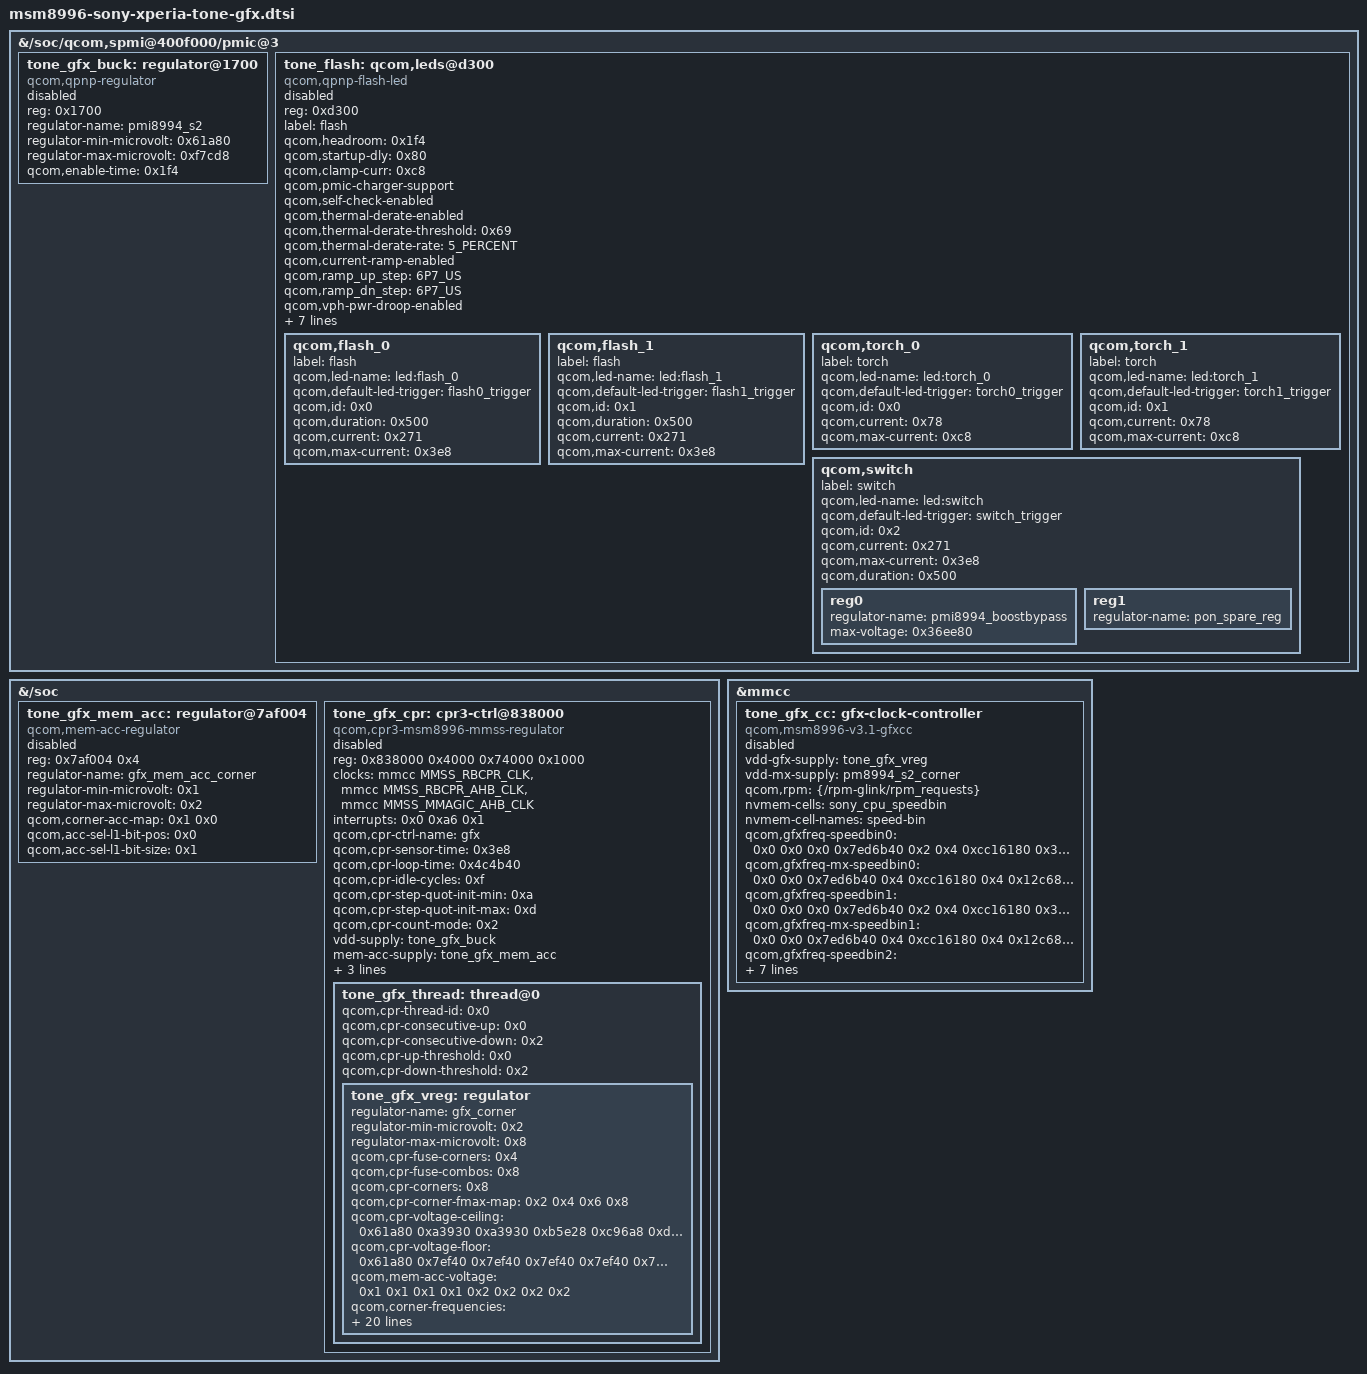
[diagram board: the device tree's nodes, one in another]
/* Copyright (c) 2014-2017, The Linux Foundation. All rights reserved.
 *
 * This program is free software; you can redistribute it and/or modify
 * it under the terms of the GNU General Public License version 2 and
 * only version 2 as published by the Free Software Foundation.
 */
/* Hardware data from the final Sony dora DT at
 * 0c295b15b6d0fb59a64e13b9e0ef2070818ef2a1, not intermediate includes.
 * Source data is retained while unsupported power chains remain disabled.
 */

#include <dt-bindings/clock/qcom,mmcc-msm8996.h>
#include "msm8996-sony-xperia-tone-corners.dtsi"

/* Preserve the original PMIC buck contract. The old qpnp-regulator frontend
 * has not been ported. Do not substitute an unverified multi-rail native
 * container: registering extra rails can alter their boot state at late init.
 */
&{/soc/qcom,spmi@400f000/pmic@3} {
	tone_gfx_buck: regulator@1700 {
		compatible = "qcom,qpnp-regulator";
		reg = <0x1700>;
		regulator-name = "pmi8994_s2";
		regulator-min-microvolt = <0x61a80>;
		regulator-max-microvolt = <0xf7cd8>;
		qcom,enable-time = <0x1f4>;
		status = "disabled";
	};

/* Legacy Sony flash safety policy; the matching VADC/charger/boost driver
	 * is not ported. A FLASH_V2 compatible does not describe this hardware. */
	tone_flash: qcom,leds@d300 {
		compatible = "qcom,qpnp-flash-led";
		reg = <0xd300>;
		label = "flash";
		qcom,headroom = <0x1f4>;
		qcom,startup-dly = <0x80>;
		qcom,clamp-curr = <0xc8>;
		qcom,pmic-charger-support;
		qcom,self-check-enabled;
		qcom,thermal-derate-enabled;
		qcom,thermal-derate-threshold = <0x69>;
		qcom,thermal-derate-rate = "5_PERCENT";
		qcom,current-ramp-enabled;
		qcom,ramp_up_step = "6P7_US";
		qcom,ramp_dn_step = "6P7_US";
		qcom,vph-pwr-droop-enabled;
		qcom,vph-pwr-droop-threshold = <0xbb8>;
		qcom,vph-pwr-droop-debounce-time = <0xa>;
		qcom,headroom-sense-ch0-enabled;
		qcom,headroom-sense-ch1-enabled;
		qcom,power-detect-enabled;
		qcom,pmic-revid = <&pmi8994_revid>;
		qcom,follow-otst2-rb-disabled;
		status = "disabled";

		qcom,flash_0 {
			label = "flash";
			qcom,led-name = "led:flash_0";
			qcom,default-led-trigger = "flash0_trigger";
			qcom,id = <0x0>;
			qcom,duration = <0x500>;
			qcom,current = <0x271>;
			qcom,max-current = <0x3e8>;
		};

		qcom,flash_1 {
			label = "flash";
			qcom,led-name = "led:flash_1";
			qcom,default-led-trigger = "flash1_trigger";
			qcom,id = <0x1>;
			qcom,duration = <0x500>;
			qcom,current = <0x271>;
			qcom,max-current = <0x3e8>;
		};

		qcom,torch_0 {
			label = "torch";
			qcom,led-name = "led:torch_0";
			qcom,default-led-trigger = "torch0_trigger";
			qcom,id = <0x0>;
			qcom,current = <0x78>;
			qcom,max-current = <0xc8>;
		};

		qcom,torch_1 {
			label = "torch";
			qcom,led-name = "led:torch_1";
			qcom,default-led-trigger = "torch1_trigger";
			qcom,id = <0x1>;
			qcom,current = <0x78>;
			qcom,max-current = <0xc8>;
		};

		qcom,switch {
			label = "switch";
			qcom,led-name = "led:switch";
			qcom,default-led-trigger = "switch_trigger";
			qcom,id = <0x2>;
			qcom,current = <0x271>;
			qcom,max-current = <0x3e8>;
			qcom,duration = <0x500>;

			reg0 {
				regulator-name = "pmi8994_boostbypass";
				max-voltage = <0x36ee80>;
			};

			reg1 {
				regulator-name = "pon_spare_reg";
			};
		};
	};
};

&{/soc} {
	tone_gfx_mem_acc: regulator@7af004 {
		compatible = "qcom,mem-acc-regulator";
		reg = <0x7af004 0x4>;
		reg-names = "acc-sel-l1";
		regulator-name = "gfx_mem_acc_corner";
		regulator-min-microvolt = <0x1>;
		regulator-max-microvolt = <0x2>;
		qcom,corner-acc-map = <0x1 0x0>;
		qcom,acc-sel-l1-bit-pos = <0x0>;
		qcom,acc-sel-l1-bit-size = <0x1>;
		status = "disabled";
	};

	tone_gfx_cpr: cpr3-ctrl@838000 {
		compatible = "qcom,cpr3-msm8996-mmss-regulator";
		reg = <0x838000 0x4000 0x74000 0x1000>;
		reg-names = "cpr_ctrl", "fuse_base";
		clocks = <&mmcc MMSS_RBCPR_CLK>, <&mmcc MMSS_RBCPR_AHB_CLK>,
			 <&mmcc MMSS_MMAGIC_AHB_CLK>;
		clock-names = "core_clk", "iface_clk", "bus_clk";
		interrupts = <0x0 0xa6 0x1>;
		interrupt-names = "cpr";
		qcom,cpr-ctrl-name = "gfx";
		qcom,cpr-sensor-time = <0x3e8>;
		qcom,cpr-loop-time = <0x4c4b40>;
		qcom,cpr-idle-cycles = <0xf>;
		qcom,cpr-step-quot-init-min = <0xa>;
		qcom,cpr-step-quot-init-max = <0xd>;
		qcom,cpr-count-mode = <0x2>;
		vdd-supply = <&tone_gfx_buck>;
		mem-acc-supply = <&tone_gfx_mem_acc>;
		qcom,voltage-step = <0x1388>;
		qcom,cpr-enable;
		qcom,cpr-aging-ref-voltage = <0xdcf28>;
		status = "disabled";

		tone_gfx_thread: thread@0 {
			qcom,cpr-thread-id = <0x0>;
			qcom,cpr-consecutive-up = <0x0>;
			qcom,cpr-consecutive-down = <0x2>;
			qcom,cpr-up-threshold = <0x0>;
			qcom,cpr-down-threshold = <0x2>;

			tone_gfx_vreg: regulator {
				regulator-name = "gfx_corner";
				regulator-min-microvolt = <0x2>;
				regulator-max-microvolt = <0x8>;
				qcom,cpr-fuse-corners = <0x4>;
				qcom,cpr-fuse-combos = <0x8>;
				qcom,cpr-corners = <0x8>;
				qcom,cpr-corner-fmax-map = <0x2 0x4 0x6 0x8>;
				qcom,cpr-voltage-ceiling = <0x61a80 0xa3930 0xa3930 0xb5e28 0xc96a8 0xdcf28 0xea600 0xf7cd8>;
				qcom,cpr-voltage-floor = <0x61a80 0x7ef40 0x7ef40 0x7ef40 0x7ef40 0x7ef40 0x7ef40 0x7ef40>;
				qcom,mem-acc-voltage = <0x1 0x1 0x1 0x1 0x2 0x2 0x2 0x2>;
				qcom,corner-frequencies = <0x0 0x7ed6b40 0xcc16180 0x12c684c0 0x17f2fb40 0x1e65fb80 0x2160ec00 0x25317c00>;
				qcom,cpr-target-quotients = <0x0 0x0 0x0 0x0 0x0 0x0 0x0 0x0
			0x0 0x0 0x0 0x0 0x0 0x0 0x0 0x0
			0x0 0x0 0x0 0x0 0x0 0x0 0xb9 0xb3
			0x123 0x12b 0x130 0x13f 0x0 0x0 0x0 0x0
			0x0 0x0 0x0 0x0 0x0 0x0 0x11f 0x111
			0x1a9 0x1aa 0x1bb 0x1c5 0x0 0x0 0x0 0x0
			0x0 0x0 0x0 0x0 0x0 0x0 0x19e 0x188
			0x248 0x240 0x260 0x264 0x0 0x0 0x0 0x0
			0x0 0x0 0x0 0x0 0x0 0x0 0x1cb 0x1af
			0x2ac 0x284 0x2b4 0x2a7 0x0 0x0 0x0 0x0
			0x0 0x0 0x0 0x0 0x0 0x0 0x241 0x21f
			0x31e 0x300 0x337 0x32a 0x0 0x0 0x0 0x0
			0x0 0x0 0x0 0x0 0x0 0x0 0x29d 0x275
			0x376 0x360 0x39c 0x38f 0x0 0x0 0x0 0x0
			0x0 0x0 0x0 0x0 0x0 0x0 0x303 0x2d5
			0x3d8 0x3ca 0x40c 0x400 0x0 0x0 0x0 0x0>;
				qcom,cpr-ro-scaling-factor = <0x0 0x0 0x0 0x0 0x0 0x0 0x7f3 0x77d
			0x7a7 0x853 0x8c6 0x8cd 0x0 0x0 0x0 0x0
			0x0 0x0 0x0 0x0 0x0 0x0 0x7f3 0x77d
			0x7a7 0x853 0x8c6 0x8cd 0x0 0x0 0x0 0x0
			0x0 0x0 0x0 0x0 0x0 0x0 0x7f3 0x77d
			0x7a7 0x853 0x8c6 0x8cd 0x0 0x0 0x0 0x0
			0x0 0x0 0x0 0x0 0x0 0x0 0x7f3 0x77d
			0x7a7 0x853 0x8c6 0x8cd 0x0 0x0 0x0 0x0
			0x0 0x0 0x0 0x0 0x0 0x0 0x7f3 0x77d
			0x7a7 0x853 0x8c6 0x8cd 0x0 0x0 0x0 0x0
			0x0 0x0 0x0 0x0 0x0 0x0 0x7f3 0x77d
			0x7a7 0x853 0x8c6 0x8cd 0x0 0x0 0x0 0x0
			0x0 0x0 0x0 0x0 0x0 0x0 0x7f3 0x77d
			0x7a7 0x853 0x8c6 0x8cd 0x0 0x0 0x0 0x0
			0x0 0x0 0x0 0x0 0x0 0x0 0x7f3 0x77d
			0x7a7 0x853 0x8c6 0x8cd 0x0 0x0 0x0 0x0>;
				qcom,cpr-open-loop-voltage-fuse-adjustment = <0x0 0x0 0x7530 0xffffd8f0 0xffff8ad0 0xffff8ad0 0x0 0xffffd8f0
			0xffff8ad0 0xffff8ad0 0x0 0xffffd8f0 0xfffeee90 0x0 0x0 0x0
			0xfffeee90 0x0 0x0 0x0 0xfffeee90 0x0 0x0 0x0
			0xfffeee90 0x0 0x0 0x0 0xfffeee90 0x0 0x0 0x0>;
				qcom,cpr-closed-loop-voltage-adjustment = <0x0 0xafc8 0xffffec78 0x4e20 0x4e20 0x7530 0x2710 0xffffec78
			0x0 0xafc8 0xffffec78 0x4e20 0x4e20 0x7530 0x2710 0xffffec78
			0x0 0x7530 0xea60 0x9c40 0x9c40 0xafc8 0x61a8 0x88b8
			0x0 0x0 0x7530 0x2710 0x2710 0xafc8 0x61a8 0x61a8
			0x0 0x0 0x7530 0x2710 0x2710 0xafc8 0x61a8 0x61a8
			0x0 0x0 0x7530 0x2710 0x2710 0xafc8 0x61a8 0x61a8
			0x0 0x0 0x7530 0x2710 0x2710 0xafc8 0x61a8 0x61a8
			0x0 0x0 0x7530 0x2710 0x2710 0xafc8 0x61a8 0x61a8>;
				qcom,cpr-floor-to-ceiling-max-range = <0x0 0x11170 0x11170 0x124f8 0x13880 0x15f90 0x17318 0x186a0>;
				qcom,cpr-fused-closed-loop-voltage-adjustment-map = <0x0 0x0 0x0 0x0 0x0 0x0 0x0 0x0
			0x0 0x0 0x0 0x0 0x0 0x0 0x0 0x0
			0x0 0x0 0x0 0x0 0x0 0x0 0x0 0x0
			0x0 0x0 0x0 0x0 0x0 0x0 0x0 0x0
			0x0 0x2 0x2 0x2 0x2 0x0 0x0 0x4
			0x0 0x2 0x2 0x2 0x2 0x0 0x0 0x4
			0x0 0x2 0x2 0x2 0x2 0x0 0x0 0x4
			0x0 0x2 0x2 0x2 0x2 0x0 0x0 0x4>;
				qcom,allow-voltage-interpolation;
				qcom,cpr-scaled-open-loop-voltage-as-ceiling;
				qcom,cpr-aging-max-voltage-adjustment = <0x3a98>;
				qcom,cpr-aging-ref-corner = <0x6>;
				qcom,cpr-aging-ro-scaling-factor = <0xb86>;
				qcom,allow-aging-voltage-adjustment = <0x0 0x0 0x0 0x1 0x1 0x1 0x1 0x1>;
			};
		};
	};

};

/* Sony CPU/MMSS clock drivers share fuse bits 29..31 at 0x74130; use
 * the existing CPU supplement cell instead of duplicating its NVMEM range. */
/* Child uses MMCC's single regmap owner; CPR needs the parent's RBCPR clocks.
 * This remains gated until the real RPM corner and physical buck frontends,
 * GX/CX sequencing, KGSL and SMMU integration have been validated.
 */
&mmcc {
	tone_gfx_cc: gfx-clock-controller {
		compatible = "qcom,msm8996-v3.1-gfxcc";
		#clock-cells = <1>;
		vdd-gfx-supply = <&tone_gfx_vreg>;
		vdd-mx-supply = <&pm8994_s2_corner>;
		qcom,rpm = <&{/rpm-glink/rpm_requests}>;
		nvmem-cells = <&sony_cpu_speedbin>;
		nvmem-cell-names = "speed-bin";
		status = "disabled";
		qcom,gfxfreq-speedbin0 = <0x0 0x0 0x0 0x7ed6b40 0x2 0x4 0xcc16180 0x3
			0x4 0x12c684c0 0x4 0x4 0x17f2fb40 0x5 0x5 0x1e65fb80
			0x6 0x5 0x2160ec00 0x7 0x7 0x25317c00 0x8 0x7>;
		qcom,gfxfreq-mx-speedbin0 = <0x0 0x0 0x7ed6b40 0x4 0xcc16180 0x4 0x12c684c0 0x4
			0x17f2fb40 0x5 0x1e65fb80 0x5 0x2160ec00 0x7 0x25317c00 0x7>;
		qcom,gfxfreq-speedbin1 = <0x0 0x0 0x0 0x7ed6b40 0x2 0x4 0xcc16180 0x3
			0x4 0x12c684c0 0x4 0x4 0x17f2fb40 0x5 0x5 0x1e65fb80
			0x6 0x5>;
		qcom,gfxfreq-mx-speedbin1 = <0x0 0x0 0x7ed6b40 0x4 0xcc16180 0x4 0x12c684c0 0x4
			0x17f2fb40 0x5 0x1e65fb80 0x5>;
		qcom,gfxfreq-speedbin2 = <0x0 0x0 0x0 0x7ed6b40 0x2 0x4 0xcc16180 0x3
			0x4 0x12c684c0 0x4 0x4 0x17f2fb40 0x5 0x5 0x1e65fb80
			0x6 0x5 0x2160ec00 0x7 0x7>;
		qcom,gfxfreq-mx-speedbin2 = <0x0 0x0 0x7ed6b40 0x4 0xcc16180 0x4 0x12c684c0 0x4
			0x17f2fb40 0x5 0x1e65fb80 0x5 0x2160ec00 0x7>;
		qcom,gfxfreq-speedbin3 = <0x0 0x0 0x0 0x7ed6b40 0x2 0x4 0xcc16180 0x3
			0x4 0x12c684c0 0x4 0x4 0x17f2fb40 0x5 0x5 0x1e65fb80
			0x6 0x5 0x2160ec00 0x7 0x7 0x25317c00 0x8 0x7>;
		qcom,gfxfreq-mx-speedbin3 = <0x0 0x0 0x7ed6b40 0x4 0xcc16180 0x4 0x12c684c0 0x4
			0x17f2fb40 0x5 0x1e65fb80 0x5 0x2160ec00 0x7 0x25317c00 0x7>;
	};
};
